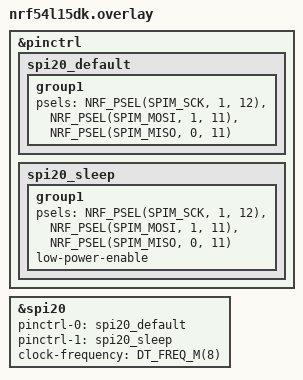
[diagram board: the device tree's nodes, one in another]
/*
 * Zephyr device tree overlay — Nordic nRF54L15-DK + EBYTE E22-900M30S (SX1262)
 *
 * Uses SPIM20 (peripheral domain SPI, flexible pin mapping).
 * SPIM00 is NOT used because its MISO pin (P2.09) conflicts with DK LED0.
 *
 * Physical wiring:
 *   E22 SCK  → P1.12
 *   E22 MOSI → P1.11
 *   E22 MISO → P0.11
 *   E22 NSS  → P0.09  (RadioLib GPIO, not hardware CS)
 *   E22 DIO1 → P0.08
 *   E22 BUSY → P0.07
 *   E22 RST  → P0.06
 *   E22 RXEN → P0.05  (held HIGH by SX126X_ANT_SW)
 */

&pinctrl {
    spi20_default: spi20_default {
        group1 {
            psels = <NRF_PSEL(SPIM_SCK,  1, 12)>,  /* P1.12 */
                    <NRF_PSEL(SPIM_MOSI, 1, 11)>,  /* P1.11 */
                    <NRF_PSEL(SPIM_MISO, 0, 11)>;  /* P0.11 */
        };
    };

    spi20_sleep: spi20_sleep {
        group1 {
            psels = <NRF_PSEL(SPIM_SCK,  1, 12)>,
                    <NRF_PSEL(SPIM_MOSI, 1, 11)>,
                    <NRF_PSEL(SPIM_MISO, 0, 11)>;
            low-power-enable;
        };
    };
};

&spi20 {
    status = "okay";
    pinctrl-0 = <&spi20_default>;
    pinctrl-1 = <&spi20_sleep>;
    pinctrl-names = "default", "sleep";
    clock-frequency = <DT_FREQ_M(8)>;  /* 8 MHz — safe for E22 over wires */

    /* CS and IRQ lines are bit-banged by RadioLib; no DT child node needed. */
};
